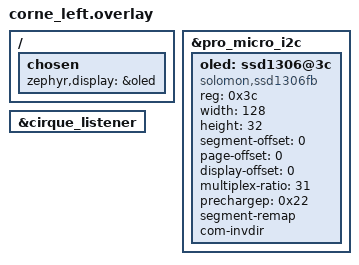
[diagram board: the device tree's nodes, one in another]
#include "corne_pointer.dtsi"

&pro_micro_i2c {
  status = "okay";

  oled: ssd1306@3c {
    compatible = "solomon,ssd1306fb";
    reg = <0x3c>;
    status = "okay";

    width = <128>;
    height = <32>;
    segment-offset = <0>;
    page-offset = <0>;
    display-offset = <0>;
    multiplex-ratio = <31>;
    prechargep = <0x22>;
    segment-remap;
    com-invdir;
  };
};

/ {
  chosen {
    zephyr,display = &oled;
  };
};

&cirque_listener {
  status = "okay";
};
